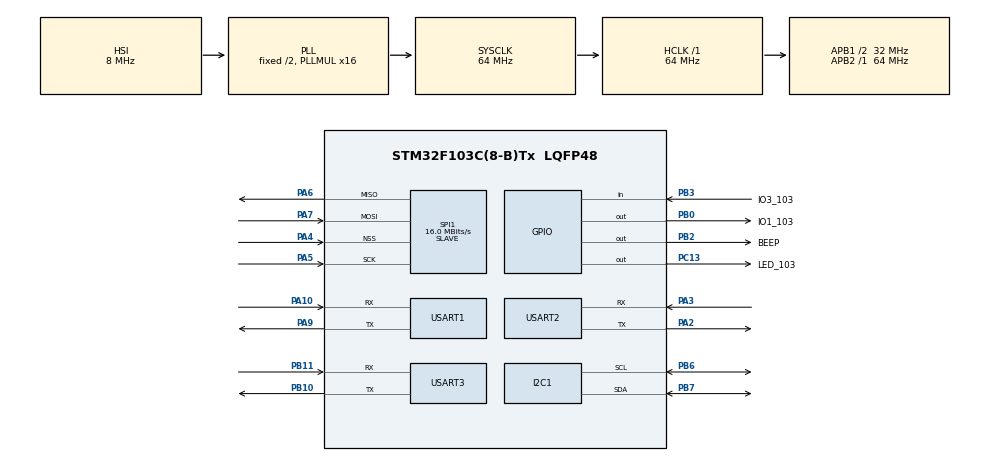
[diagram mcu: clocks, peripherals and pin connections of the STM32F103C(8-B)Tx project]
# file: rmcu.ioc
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ADC1.Channel-0\#ChannelRegularConversion=ADC_CHANNEL_TEMPSENSOR
ADC1.Channel-1\#ChannelInjectedConversion=ADC_CHANNEL_TEMPSENSOR
ADC1.ContinuousConvMode=DISABLE
ADC1.DataAlign=ADC_DATAALIGN_RIGHT
ADC1.DiscontinuousConvMode=DISABLE
ADC1.EnableAnalogWatchDog=false
ADC1.EnableRegularConversion=ENABLE
ADC1.ExternalTrigConv=ADC_SOFTWARE_START
ADC1.ExternalTrigInjecConv=ADC_EXTERNALTRIGINJECCONV_T4_TRGO
ADC1.InjNumberOfConversion=1
ADC1.InjectedConvMode=None
ADC1.InjectedOffset-1\#ChannelInjectedConversion=0
ADC1.NbrOfConversion=1
ADC1.NbrOfConversionFlag=1
ADC1.Rank-0\#ChannelRegularConversion=1
ADC1.Rank-1\#ChannelInjectedConversion=1
ADC1.SamplingTime-0\#ChannelRegularConversion=ADC_SAMPLETIME_1CYCLE_5
ADC1.SamplingTime-1\#ChannelInjectedConversion=ADC_SAMPLETIME_71CYCLES_5
ADC1.ScanConvMode=ADC_SCAN_DISABLE
ADC1.master=1
I2C1.I2C_Mode=I2C_Standard
I2C1.OwnAddress=0x30
IWDG.Prescaler=IWDG_PRESCALER_32
Mcu.Family=STM32F1
Mcu.Name=STM32F103C(8-B)Tx
Mcu.Package=LQFP48
NVIC.ADC1_2_IRQn=true\:5\:0\:true\:false\:true\:true
NVIC.I2C1_EV_IRQn=true\:4\:0\:true\:false\:true\:true
NVIC.PriorityGroup=NVIC_PRIORITYGROUP_3
NVIC.SPI1_IRQn=true\:4\:0\:true\:false\:true\:true
NVIC.TIM3_IRQn=true\:7\:0\:true\:false\:true\:true
NVIC.USART1_IRQn=true\:7\:0\:true\:false\:true\:true
NVIC.USART2_IRQn=true\:7\:0\:true\:false\:true\:true
PA10.Mode=Asynchronous
PA10.Signal=USART1_RX
PA13.Mode=Serial_Wire
PA13.Signal=SYS_JTMS-SWDIO
PA14.Mode=Serial_Wire
PA14.Signal=SYS_JTCK-SWCLK
PA2.Mode=Asynchronous
PA2.Signal=USART2_TX
PA3.Mode=Asynchronous
PA3.Signal=USART2_RX
PA4.Mode=NSS_Signal_Hard_Input
PA4.Signal=SPI1_NSS
PA5.Mode=Full_Duplex_Slave
PA5.Signal=SPI1_SCK
PA6.Mode=Full_Duplex_Slave
PA6.Signal=SPI1_MISO
PA7.Mode=Full_Duplex_Slave
PA7.Signal=SPI1_MOSI
PA9.Mode=Asynchronous
PA9.Signal=USART1_TX
PB0.GPIO_Label=IO1_103
PB0.Signal=GPIO_Output
PB10.Mode=Asynchronous
PB10.Signal=USART3_TX
PB11.Mode=Asynchronous
PB11.Signal=USART3_RX
PB2.GPIO_Label=BEEP
PB2.Signal=GPIO_Output
PB3.GPIO_Label=IO3_103
PB3.GPIO_PuPd=GPIO_PULLUP
PB3.Signal=GPIO_Input
PB6.Mode=I2C
PB6.Signal=I2C1_SCL
PB7.Mode=I2C
PB7.Signal=I2C1_SDA
PC13-TAMPER-RTC.GPIO_Label=LED_103
PC13-TAMPER-RTC.Signal=GPIO_Output
ProjectManager.HeapSize=0x200
ProjectManager.StackSize=0x400
ProjectManager.TargetToolchain=MDK-ARM V5
RCC.ADCPresc=RCC_ADCPCLK2_DIV8
RCC.AHBFreq_Value=64000000
RCC.APB1CLKDivider=RCC_HCLK_DIV2
RCC.APB1Freq_Value=32000000
RCC.APB1TimFreq_Value=64000000
RCC.APB2Freq_Value=64000000
RCC.APB2TimFreq_Value=64000000
RCC.HCLKFreq_Value=64000000
RCC.PLLMUL=RCC_PLL_MUL16
RCC.SYSCLKFreq_VALUE=64000000
RCC.SYSCLKSource=RCC_SYSCLKSOURCE_PLLCLK
RCC.USBFreq_Value=64000000
SPI1.BaudRatePrescaler=SPI_BAUDRATEPRESCALER_4
SPI1.CalculateBaudRate=16.0 MBits/s
SPI1.Direction=SPI_DIRECTION_2LINES
SPI1.Mode=SPI_MODE_SLAVE
SPI1.VirtualNSS=VM_NSSHARD
SPI1.VirtualType=VM_SLAVE
TIM2.Period=1000
TIM2.Prescaler=71
TIM2.TIM_MasterOutputTrigger=TIM_TRGO_UPDATE
TIM3.AutoReloadPreload=TIM_AUTORELOAD_PRELOAD_ENABLE
TIM3.Period=250
TIM3.Prescaler=71
TIM4.Period=10000
TIM4.Prescaler=7199
TIM4.TIM_MasterOutputTrigger=TIM_TRGO_UPDATE
USART1.VirtualMode=VM_ASYNC
USART2.VirtualMode=VM_ASYNC
USART3.VirtualMode=VM_ASYNC
VP_ADC1_TempSens_Input.Mode=IN-TempSens
VP_IWDG_VS_IWDG.Mode=IWDG_Activate
VP_TIM2_VS_ClockSourceINT.Mode=Internal
VP_TIM3_VS_ClockSourceINT.Mode=Internal
VP_TIM4_VS_ClockSourceINT.Mode=Internal
board=rmcu

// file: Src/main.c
/**
  ******************************************************************************
  * @file           : main.c
  * @brief          : Main program body
  ******************************************************************************
  ** This notice applies to any and all portions of this file
  * that are not between comment pairs USER CODE BEGIN and
  * USER CODE END. Other portions of this file, whether
  * inserted by the user or by software development tools
  * are owned by their respective copyright owners.
  *
  * COPYRIGHT(c) 2018 STMicroelectronics
  *
  * Redistribution and use in source and binary forms, with or without modification,
  * are permitted provided that the following conditions are met:
  *   1. Redistributions of source code must retain the above copyright notice,
  *      this list of conditions and the following disclaimer.
  *   2. Redistributions in binary form must reproduce the above copyright notice,
  *      this list of conditions and the following disclaimer in the documentation
  *      and/or other materials provided with the distribution.
  *   3. Neither the name of STMicroelectronics nor the names of its contributors
  *      may be used to endorse or promote products derived from this software
  *      without specific prior written permission.
  *
  * THIS SOFTWARE IS PROVIDED BY THE COPYRIGHT HOLDERS AND CONTRIBUTORS "AS IS"
  * AND ANY EXPRESS OR IMPLIED WARRANTIES, INCLUDING, BUT NOT LIMITED TO, THE
  * IMPLIED WARRANTIES OF MERCHANTABILITY AND FITNESS FOR A PARTICULAR PURPOSE ARE
  * DISCLAIMED. IN NO EVENT SHALL THE COPYRIGHT HOLDER OR CONTRIBUTORS BE LIABLE
  * FOR ANY DIRECT, INDIRECT, INCIDENTAL, SPECIAL, EXEMPLARY, OR CONSEQUENTIAL
  * DAMAGES (INCLUDING, BUT NOT LIMITED TO, PROCUREMENT OF SUBSTITUTE GOODS OR
  * SERVICES; LOSS OF USE, DATA, OR PROFITS; OR BUSINESS INTERRUPTION) HOWEVER
  * CAUSED AND ON ANY THEORY OF LIABILITY, WHETHER IN CONTRACT, STRICT LIABILITY,
  * OR TORT (INCLUDING NEGLIGENCE OR OTHERWISE) ARISING IN ANY WAY OUT OF THE USE
  * OF THIS SOFTWARE, EVEN IF ADVISED OF THE POSSIBILITY OF SUCH DAMAGE.
  *
  ******************************************************************************
  */
#include "main.h"
#include "stm32f1xx_hal.h"

/* USER CODE BEGIN Includes */
#include "top.h"
#include "beep.h"
#include "commu.h"

/* USER CODE END Includes */

ADC_HandleTypeDef hadc1;

I2C_HandleTypeDef hi2c1;

IWDG_HandleTypeDef hiwdg;

SPI_HandleTypeDef hspi1;

TIM_HandleTypeDef htim2;
TIM_HandleTypeDef htim3;
TIM_HandleTypeDef htim4;

UART_HandleTypeDef huart1;
UART_HandleTypeDef huart2;
UART_HandleTypeDef huart3;

/* USER CODE BEGIN PV */
/* Private variables ---------------------------------------------------------*/

/* USER CODE END PV */

void SystemClock_Config(void);
static void MX_GPIO_Init(void);
static void MX_ADC1_Init(void);
static void MX_I2C1_Init(void);
static void MX_IWDG_Init(void);
static void MX_SPI1_Init(void);
static void MX_TIM2_Init(void);
static void MX_TIM3_Init(void);
static void MX_TIM4_Init(void);
static void MX_USART1_UART_Init(void);
static void MX_USART2_UART_Init(void);
static void MX_USART3_UART_Init(void);

/* USER CODE BEGIN PFP */
/* Private function prototypes -----------------------------------------------*/

/* USER CODE END PFP */

int main(void)
{

  /* MCU Configuration----------------------------------------------------------*/

  /* Reset of all peripherals, Initializes the Flash interface and the Systick. */
  HAL_Init();

  /* Configure the system clock */
  SystemClock_Config();

  /* Initialize all configured peripherals */
  MX_GPIO_Init();
  MX_ADC1_Init();
  MX_I2C1_Init();
  MX_IWDG_Init();
  MX_SPI1_Init();
  MX_TIM2_Init();
  MX_TIM3_Init();
  MX_TIM4_Init();
  MX_USART1_UART_Init();
  MX_USART2_UART_Init();
  MX_USART3_UART_Init();
  /* USER CODE BEGIN 2 */
	AppInit();
  /* USER CODE END 2 */

  /* Infinite loop */
  while (1)
  {
	AppMain();
  }

}

void SystemClock_Config(void)
{

  RCC_OscInitTypeDef RCC_OscInitStruct;
  RCC_ClkInitTypeDef RCC_ClkInitStruct;
  RCC_PeriphCLKInitTypeDef PeriphClkInit;

    /**Initializes the CPU, AHB and APB busses clocks
    */
  RCC_OscInitStruct.OscillatorType = RCC_OSCILLATORTYPE_HSI|RCC_OSCILLATORTYPE_LSI;
  RCC_OscInitStruct.HSIState = RCC_HSI_ON;
  RCC_OscInitStruct.HSICalibrationValue = 16;
  RCC_OscInitStruct.LSIState = RCC_LSI_ON;
  RCC_OscInitStruct.PLL.PLLState = RCC_PLL_ON;
  RCC_OscInitStruct.PLL.PLLSource = RCC_PLLSOURCE_HSI_DIV2;
  RCC_OscInitStruct.PLL.PLLMUL = RCC_PLL_MUL16;
  if (HAL_RCC_OscConfig(&RCC_OscInitStruct) != HAL_OK)
  {
    _Error_Handler(__FILE__, __LINE__);
  }

    /**Initializes the CPU, AHB and APB busses clocks
    */
  RCC_ClkInitStruct.ClockType = RCC_CLOCKTYPE_HCLK|RCC_CLOCKTYPE_SYSCLK
                              |RCC_CLOCKTYPE_PCLK1|RCC_CLOCKTYPE_PCLK2;
  RCC_ClkInitStruct.SYSCLKSource = RCC_SYSCLKSOURCE_PLLCLK;
  RCC_ClkInitStruct.AHBCLKDivider = RCC_SYSCLK_DIV1;
  RCC_ClkInitStruct.APB1CLKDivider = RCC_HCLK_DIV2;
  RCC_ClkInitStruct.APB2CLKDivider = RCC_HCLK_DIV1;

  if (HAL_RCC_ClockConfig(&RCC_ClkInitStruct, FLASH_LATENCY_2) != HAL_OK)
  {
    _Error_Handler(__FILE__, __LINE__);
  }

  PeriphClkInit.PeriphClockSelection = RCC_PERIPHCLK_ADC;
  PeriphClkInit.AdcClockSelection = RCC_ADCPCLK2_DIV8;
  if (HAL_RCCEx_PeriphCLKConfig(&PeriphClkInit) != HAL_OK)
  {
    _Error_Handler(__FILE__, __LINE__);
  }

    /**Configure the Systick interrupt time
    */
  HAL_SYSTICK_Config(HAL_RCC_GetHCLKFreq()/1000);

    /**Configure the Systick
    */
  HAL_SYSTICK_CLKSourceConfig(SYSTICK_CLKSOURCE_HCLK);

  /* SysTick_IRQn interrupt configuration */
  HAL_NVIC_SetPriority(SysTick_IRQn, 0, 0);
}

/* ADC1 init function */
static void MX_ADC1_Init(void)
{

  ADC_ChannelConfTypeDef sConfig;
  ADC_InjectionConfTypeDef sConfigInjected;

    /**Common config
    */
  hadc1.Instance = ADC1;
  hadc1.Init.ScanConvMode = ADC_SCAN_DISABLE;
  hadc1.Init.ContinuousConvMode = DISABLE;
  hadc1.Init.DiscontinuousConvMode = DISABLE;
  hadc1.Init.ExternalTrigConv = ADC_SOFTWARE_START;
  hadc1.Init.DataAlign = ADC_DATAALIGN_RIGHT;
  hadc1.Init.NbrOfConversion = 1;
  if (HAL_ADC_Init(&hadc1) != HAL_OK)
  {
    _Error_Handler(__FILE__, __LINE__);
  }

    /**Configure Regular Channel
    */
  sConfig.Channel = ADC_CHANNEL_TEMPSENSOR;
  sConfig.Rank = ADC_REGULAR_RANK_1;
  sConfig.SamplingTime = ADC_SAMPLETIME_1CYCLE_5;
  if (HAL_ADC_ConfigChannel(&hadc1, &sConfig) != HAL_OK)
  {
    _Error_Handler(__FILE__, __LINE__);
  }

    /**Configure Injected Channel
    */
  sConfigInjected.InjectedChannel = ADC_CHANNEL_TEMPSENSOR;
  sConfigInjected.InjectedRank = ADC_INJECTED_RANK_1;
  sConfigInjected.InjectedNbrOfConversion = 1;
  sConfigInjected.InjectedSamplingTime = ADC_SAMPLETIME_71CYCLES_5;
  sConfigInjected.ExternalTrigInjecConv = ADC_EXTERNALTRIGINJECCONV_T4_TRGO;
  sConfigInjected.AutoInjectedConv = DISABLE;
  sConfigInjected.InjectedDiscontinuousConvMode = DISABLE;
  sConfigInjected.InjectedOffset = 0;
  if (HAL_ADCEx_InjectedConfigChannel(&hadc1, &sConfigInjected) != HAL_OK)
  {
    _Error_Handler(__FILE__, __LINE__);
  }

}

/* I2C1 init function */
static void MX_I2C1_Init(void)
{

  hi2c1.Instance = I2C1;
  hi2c1.Init.ClockSpeed = 100000;
  hi2c1.Init.DutyCycle = I2C_DUTYCYCLE_2;
  hi2c1.Init.OwnAddress1 = 96;
  hi2c1.Init.AddressingMode = I2C_ADDRESSINGMODE_7BIT;
  hi2c1.Init.DualAddressMode = I2C_DUALADDRESS_DISABLE;
  hi2c1.Init.OwnAddress2 = 0;
  hi2c1.Init.GeneralCallMode = I2C_GENERALCALL_DISABLE;
  hi2c1.Init.NoStretchMode = I2C_NOSTRETCH_DISABLE;
  if (HAL_I2C_Init(&hi2c1) != HAL_OK)
  {
    _Error_Handler(__FILE__, __LINE__);
  }

}

/* IWDG init function */
static void MX_IWDG_Init(void)
{

  hiwdg.Instance = IWDG;
  hiwdg.Init.Prescaler = IWDG_PRESCALER_32;
  hiwdg.Init.Reload = 4095;
  if (HAL_IWDG_Init(&hiwdg) != HAL_OK)
  {
    _Error_Handler(__FILE__, __LINE__);
  }

}

/* SPI1 init function */
static void MX_SPI1_Init(void)
{

  /* SPI1 parameter configuration*/
  hspi1.Instance = SPI1;
  hspi1.Init.Mode = SPI_MODE_SLAVE;
  hspi1.Init.Direction = SPI_DIRECTION_2LINES;
  hspi1.Init.DataSize = SPI_DATASIZE_8BIT;
  hspi1.Init.CLKPolarity = SPI_POLARITY_LOW;
  hspi1.Init.CLKPhase = SPI_PHASE_1EDGE;
  hspi1.Init.NSS = SPI_NSS_HARD_INPUT;
  hspi1.Init.BaudRatePrescaler = SPI_BAUDRATEPRESCALER_4;
  hspi1.Init.FirstBit = SPI_FIRSTBIT_MSB;
  hspi1.Init.TIMode = SPI_TIMODE_DISABLE;
  hspi1.Init.CRCCalculation = SPI_CRCCALCULATION_DISABLE;
  hspi1.Init.CRCPolynomial = 10;
  if (HAL_SPI_Init(&hspi1) != HAL_OK)
  {
    _Error_Handler(__FILE__, __LINE__);
  }

}

/* TIM2 init function */
static void MX_TIM2_Init(void)
{

  TIM_ClockConfigTypeDef sClockSourceConfig;
  TIM_MasterConfigTypeDef sMasterConfig;

  htim2.Instance = TIM2;
  htim2.Init.Prescaler = 71;
  htim2.Init.CounterMode = TIM_COUNTERMODE_UP;
  htim2.Init.Period = 1000;
  htim2.Init.ClockDivision = TIM_CLOCKDIVISION_DIV1;
  htim2.Init.AutoReloadPreload = TIM_AUTORELOAD_PRELOAD_DISABLE;
  if (HAL_TIM_Base_Init(&htim2) != HAL_OK)
  {
    _Error_Handler(__FILE__, __LINE__);
  }

  sClockSourceConfig.ClockSource = TIM_CLOCKSOURCE_INTERNAL;
  if (HAL_TIM_ConfigClockSource(&htim2, &sClockSourceConfig) != HAL_OK)
  {
    _Error_Handler(__FILE__, __LINE__);
  }

  sMasterConfig.MasterOutputTrigger = TIM_TRGO_UPDATE;
  sMasterConfig.MasterSlaveMode = TIM_MASTERSLAVEMODE_DISABLE;
  if (HAL_TIMEx_MasterConfigSynchronization(&htim2, &sMasterConfig) != HAL_OK)
  {
    _Error_Handler(__FILE__, __LINE__);
  }

}

/* TIM3 init function */
static void MX_TIM3_Init(void)
{

  TIM_ClockConfigTypeDef sClockSourceConfig;
  TIM_MasterConfigTypeDef sMasterConfig;

  htim3.Instance = TIM3;
  htim3.Init.Prescaler = 71;
  htim3.Init.CounterMode = TIM_COUNTERMODE_UP;
  htim3.Init.Period = 250;
  htim3.Init.ClockDivision = TIM_CLOCKDIVISION_DIV1;
  htim3.Init.AutoReloadPreload = TIM_AUTORELOAD_PRELOAD_ENABLE;
  if (HAL_TIM_Base_Init(&htim3) != HAL_OK)
  {
    _Error_Handler(__FILE__, __LINE__);
  }

  sClockSourceConfig.ClockSource = TIM_CLOCKSOURCE_INTERNAL;
  if (HAL_TIM_ConfigClockSource(&htim3, &sClockSourceConfig) != HAL_OK)
  {
    _Error_Handler(__FILE__, __LINE__);
  }

  sMasterConfig.MasterOutputTrigger = TIM_TRGO_RESET;
  sMasterConfig.MasterSlaveMode = TIM_MASTERSLAVEMODE_DISABLE;
  if (HAL_TIMEx_MasterConfigSynchronization(&htim3, &sMasterConfig) != HAL_OK)
  {
    _Error_Handler(__FILE__, __LINE__);
  }

}

/* TIM4 init function */
static void MX_TIM4_Init(void)
{

  TIM_ClockConfigTypeDef sClockSourceConfig;
  TIM_MasterConfigTypeDef sMasterConfig;

  htim4.Instance = TIM4;
  htim4.Init.Prescaler = 7199;
  htim4.Init.CounterMode = TIM_COUNTERMODE_UP;
  htim4.Init.Period = 10000;
  htim4.Init.ClockDivision = TIM_CLOCKDIVISION_DIV1;
  htim4.Init.AutoReloadPreload = TIM_AUTORELOAD_PRELOAD_DISABLE;
  if (HAL_TIM_Base_Init(&htim4) != HAL_OK)
  {
    _Error_Handler(__FILE__, __LINE__);
  }

  sClockSourceConfig.ClockSource = TIM_CLOCKSOURCE_INTERNAL;
  if (HAL_TIM_ConfigClockSource(&htim4, &sClockSourceConfig) != HAL_OK)
  {
    _Error_Handler(__FILE__, __LINE__);
  }

  sMasterConfig.MasterOutputTrigger = TIM_TRGO_UPDATE;
  sMasterConfig.MasterSlaveMode = TIM_MASTERSLAVEMODE_DISABLE;
  if (HAL_TIMEx_MasterConfigSynchronization(&htim4, &sMasterConfig) != HAL_OK)
  {
    _Error_Handler(__FILE__, __LINE__);
  }

}

/* USART1 init function */
static void MX_USART1_UART_Init(void)
{

  huart1.Instance = USART1;
  huart1.Init.BaudRate = 115200;
  huart1.Init.WordLength = UART_WORDLENGTH_8B;
  huart1.Init.StopBits = UART_STOPBITS_1;
  huart1.Init.Parity = UART_PARITY_NONE;
  huart1.Init.Mode = UART_MODE_TX_RX;
  huart1.Init.HwFlowCtl = UART_HWCONTROL_NONE;
  huart1.Init.OverSampling = UART_OVERSAMPLING_16;
  if (HAL_UART_Init(&huart1) != HAL_OK)
  {
    _Error_Handler(__FILE__, __LINE__);
  }

}

/* USART2 init function */
static void MX_USART2_UART_Init(void)
{

  huart2.Instance = USART2;
  huart2.Init.BaudRate = 115200;
  huart2.Init.WordLength = UART_WORDLENGTH_8B;
  huart2.Init.StopBits = UART_STOPBITS_1;
  huart2.Init.Parity = UART_PARITY_NONE;
  huart2.Init.Mode = UART_MODE_TX_RX;
  huart2.Init.HwFlowCtl = UART_HWCONTROL_NONE;
  huart2.Init.OverSampling = UART_OVERSAMPLING_16;
  if (HAL_UART_Init(&huart2) != HAL_OK)
  {
    _Error_Handler(__FILE__, __LINE__);
  }

}

/* USART3 init function */
static void MX_USART3_UART_Init(void)
{

  huart3.Instance = USART3;
  huart3.Init.BaudRate = 115200;
  huart3.Init.WordLength = UART_WORDLENGTH_8B;
  huart3.Init.StopBits = UART_STOPBITS_1;
  huart3.Init.Parity = UART_PARITY_NONE;
  huart3.Init.Mode = UART_MODE_TX_RX;
  huart3.Init.HwFlowCtl = UART_HWCONTROL_NONE;
  huart3.Init.OverSampling = UART_OVERSAMPLING_16;
  if (HAL_UART_Init(&huart3) != HAL_OK)
  {
    _Error_Handler(__FILE__, __LINE__);
  }

}

/** Configure pins as
        * Analog
        * Input
        * Output
        * EVENT_OUT
        * EXTI
*/
static void MX_GPIO_Init(void)
{

  GPIO_InitTypeDef GPIO_InitStruct;

  /* GPIO Ports Clock Enable */
  __HAL_RCC_GPIOC_CLK_ENABLE();
  __HAL_RCC_GPIOA_CLK_ENABLE();
  __HAL_RCC_GPIOB_CLK_ENABLE();

  /*Configure GPIO pin Output Level */
  HAL_GPIO_WritePin(LED_103_GPIO_Port, LED_103_Pin, GPIO_PIN_RESET);

  /*Configure GPIO pin Output Level */
  HAL_GPIO_WritePin(GPIOB, IO1_103_Pin|BEEP_Pin, GPIO_PIN_RESET);

  /*Configure GPIO pin : LED_103_Pin */
  GPIO_InitStruct.Pin = LED_103_Pin;
  GPIO_InitStruct.Mode = GPIO_MODE_OUTPUT_PP;
  GPIO_InitStruct.Speed = GPIO_SPEED_FREQ_LOW;
  HAL_GPIO_Init(LED_103_GPIO_Port, &GPIO_InitStruct);

  /*Configure GPIO pins : IO1_103_Pin BEEP_Pin */
  GPIO_InitStruct.Pin = IO1_103_Pin|BEEP_Pin;
  GPIO_InitStruct.Mode = GPIO_MODE_OUTPUT_PP;
  GPIO_InitStruct.Speed = GPIO_SPEED_FREQ_LOW;
  HAL_GPIO_Init(GPIOB, &GPIO_InitStruct);

  /*Configure GPIO pin : IO3_103_Pin */
  GPIO_InitStruct.Pin = IO3_103_Pin;
  GPIO_InitStruct.Mode = GPIO_MODE_INPUT;
  GPIO_InitStruct.Pull = GPIO_PULLUP;
  HAL_GPIO_Init(IO3_103_GPIO_Port, &GPIO_InitStruct);

}

void _Error_Handler(char *file, int line)
{
  while(1)
  {
  }
}

/************************ (C) COPYRIGHT STMicroelectronics *****END OF FILE****/
